AUTOSAR XML (schema 4-0-3)
package /ComponentTypes
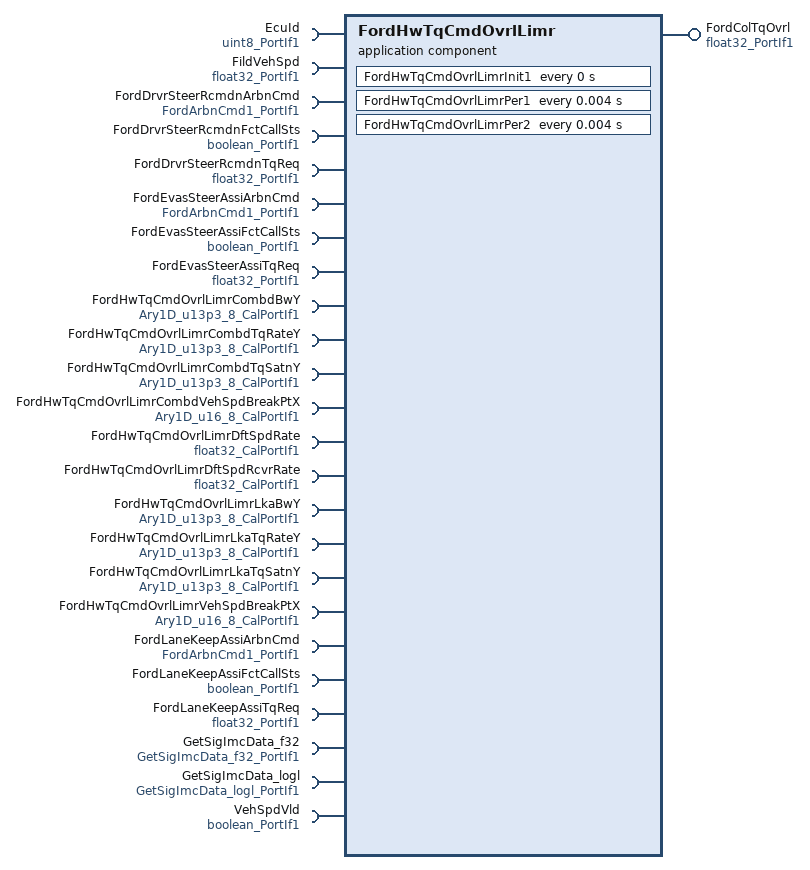
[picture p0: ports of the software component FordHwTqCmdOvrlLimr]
  application sw component type FordHwTqCmdOvrlLimr
    provide port FordColTqOvrl: nonqueued-sender-com-spec{data-element=Val, init-value=0}, provided-interface=float32_PortIf1
    24 x require port:
      EcuId: nonqueued-receiver-com-spec{data-element=Val, filter=data-filter-type=ALWAYS, init-value=0}, required-interface=uint8_PortIf1
      FildVehSpd: nonqueued-receiver-com-spec{data-element=Val, filter=data-filter-type=ALWAYS, init-value=100}, required-interface=float32_PortIf1
      FordDrvrSteerRcmdnArbnCmd: nonqueued-receiver-com-spec{data-element=Val, filter=data-filter-type=ALWAYS, init-value=0}, required-interface=FordArbnCmd1_PortIf1
      FordDrvrSteerRcmdnFctCallSts: nonqueued-receiver-com-spec{data-element=Logl, filter=data-filter-type=ALWAYS, init-value=0}, required-interface=boolean_PortIf1
      FordDrvrSteerRcmdnTqReq: nonqueued-receiver-com-spec{data-element=Val, filter=data-filter-type=ALWAYS, init-value=0}, required-interface=float32_PortIf1
      FordEvasSteerAssiArbnCmd: nonqueued-receiver-com-spec{data-element=Val, filter=data-filter-type=ALWAYS, init-value=0}, required-interface=FordArbnCmd1_PortIf1
      FordEvasSteerAssiFctCallSts: nonqueued-receiver-com-spec{data-element=Logl, filter=data-filter-type=ALWAYS, init-value=0}, required-interface=boolean_PortIf1
      FordEvasSteerAssiTqReq: nonqueued-receiver-com-spec{data-element=Val, filter=data-filter-type=ALWAYS, init-value=0}, required-interface=float32_PortIf1
      FordHwTqCmdOvrlLimrCombdBwY: parameter-require-com-spec{init-value=8 x 0, parameter=Ary1D}, required-interface=Ary1D_u13p3_8_CalPortIf1
      FordHwTqCmdOvrlLimrCombdTqRateY: parameter-require-com-spec{init-value=8 x 64, parameter=Ary1D}, required-interface=Ary1D_u13p3_8_CalPortIf1
      FordHwTqCmdOvrlLimrCombdTqSatnY: parameter-require-com-spec{init-value=8 x 0, parameter=Ary1D}, required-interface=Ary1D_u13p3_8_CalPortIf1
      FordHwTqCmdOvrlLimrCombdVehSpdBreakPtX: parameter-require-com-spec{init-value=[0, 15, 60, 100, 150, 180, 200, 250], parameter=Ary1D}, required-interface=Ary1D_u16_8_CalPortIf1
      FordHwTqCmdOvrlLimrDftSpdRate: parameter-require-com-spec{init-value=40, parameter=Val}, required-interface=float32_CalPortIf1
      FordHwTqCmdOvrlLimrDftSpdRcvrRate: parameter-require-com-spec{init-value=40, parameter=Val}, required-interface=float32_CalPortIf1
      FordHwTqCmdOvrlLimrLkaBwY: parameter-require-com-spec{init-value=8 x 0, parameter=Ary1D}, required-interface=Ary1D_u13p3_8_CalPortIf1
      FordHwTqCmdOvrlLimrLkaTqRateY: parameter-require-com-spec{init-value=8 x 40, parameter=Ary1D}, required-interface=Ary1D_u13p3_8_CalPortIf1
      FordHwTqCmdOvrlLimrLkaTqSatnY: parameter-require-com-spec{init-value=8 x 0, parameter=Ary1D}, required-interface=Ary1D_u13p3_8_CalPortIf1
      FordHwTqCmdOvrlLimrVehSpdBreakPtX: parameter-require-com-spec{init-value=[0, 15, 60, 100, 150, 180, 200, 250], parameter=Ary1D}, required-interface=Ary1D_u16_8_CalPortIf1
      FordLaneKeepAssiArbnCmd: nonqueued-receiver-com-spec{data-element=Val, filter=data-filter-type=ALWAYS, init-value=0}, required-interface=FordArbnCmd1_PortIf1
      FordLaneKeepAssiFctCallSts: nonqueued-receiver-com-spec{data-element=Logl, filter=data-filter-type=ALWAYS, init-value=0}, required-interface=boolean_PortIf1
      FordLaneKeepAssiTqReq: nonqueued-receiver-com-spec{data-element=Val, filter=data-filter-type=ALWAYS, init-value=0}, required-interface=float32_PortIf1
      GetSigImcData_f32: required-interface=GetSigImcData_f32_PortIf1
      GetSigImcData_logl: required-interface=GetSigImcData_logl_PortIf1
      VehSpdVld: nonqueued-receiver-com-spec{data-element=Logl, filter=data-filter-type=ALWAYS, init-value=1}, required-interface=boolean_PortIf1
    behavior FordHwTqCmdOvrlLimr_InternalBehavior
      ar-typed-per-instance-memorys:
        6 x data, all with sw-calibration-access=READ-ONLY:
          LimrDftVehSpd: type=boolean
          LimrVehSpdPrev: type=float32
          LkaTqReqPrev: type=float32
          PrevDftVehSpd: type=float32
          PrevVehSpd: type=float32
          TqReqPrev: type=float32
      timing event FordHwTqCmdOvrlLimr_InitEvent: start-on-event=FordHwTqCmdOvrlLimrInit1, period=0
      timing event TMT_FordHwTqCmdOvrlLimrPer1: start-on-event=FordHwTqCmdOvrlLimrPer1, period=0.004
      timing event TMT_FordHwTqCmdOvrlLimrPer2: start-on-event=FordHwTqCmdOvrlLimrPer2, period=0.004
      explicit-inter-runnable-variables:
        8 x data:
          DrvrSteerRcmdnFctCallSts: type=boolean, init-value=0
          DrvrSteerRcmdnTqReq: type=float32, init-value=0
          EvasSteerAssiFctCallSts: type=boolean, init-value=0
          EvasSteerAssiTqReq: type=float32, init-value=0
          FildVehSpdVal: type=float32, init-value=100
          LaneKeepAssiFctCallSts: type=boolean, init-value=0
          LaneKeepAssiTqReq: type=float32, init-value=0
          VehSpdVldVal: type=boolean, init-value=1
      port-api-options:
        enable-take-address=false, indirect-api=false, port=EcuId
        enable-take-address=false, indirect-api=false, port=FildVehSpd
        enable-take-address=false, indirect-api=false, port=FordColTqOvrl
        enable-take-address=false, indirect-api=false, port=FordDrvrSteerRcmdnArbnCmd
        enable-take-address=false, indirect-api=false, port=FordDrvrSteerRcmdnFctCallSts
        enable-take-address=false, indirect-api=false, port=FordDrvrSteerRcmdnTqReq
        enable-take-address=false, indirect-api=false, port=FordEvasSteerAssiArbnCmd
        enable-take-address=false, indirect-api=false, port=FordEvasSteerAssiFctCallSts
        enable-take-address=false, indirect-api=false, port=FordEvasSteerAssiTqReq
        enable-take-address=false, indirect-api=false, port=FordHwTqCmdOvrlLimrCombdBwY
        enable-take-address=false, indirect-api=false, port=FordHwTqCmdOvrlLimrCombdTqRateY
        enable-take-address=false, indirect-api=false, port=FordHwTqCmdOvrlLimrCombdTqSatnY
        enable-take-address=false, indirect-api=false, port=FordHwTqCmdOvrlLimrCombdVehSpdBreakPtX
        enable-take-address=false, indirect-api=false, port=FordHwTqCmdOvrlLimrDftSpdRate
        enable-take-address=false, indirect-api=false, port=FordHwTqCmdOvrlLimrDftSpdRcvrRate
        enable-take-address=false, indirect-api=false, port=FordHwTqCmdOvrlLimrLkaBwY
        enable-take-address=false, indirect-api=false, port=FordHwTqCmdOvrlLimrLkaTqRateY
        enable-take-address=false, indirect-api=false, port=FordHwTqCmdOvrlLimrLkaTqSatnY
        enable-take-address=false, indirect-api=false, port=FordHwTqCmdOvrlLimrVehSpdBreakPtX
        enable-take-address=false, indirect-api=false, port=FordLaneKeepAssiArbnCmd
        enable-take-address=false, indirect-api=false, port=FordLaneKeepAssiFctCallSts
        enable-take-address=false, indirect-api=false, port=FordLaneKeepAssiTqReq
        enable-take-address=false, indirect-api=false, port=GetSigImcData_f32
        enable-take-address=false, indirect-api=false, port=GetSigImcData_logl
        enable-take-address=false, indirect-api=false, port=VehSpdVld
      runnable FordHwTqCmdOvrlLimrInit1
      runnable FordHwTqCmdOvrlLimrPer1
        data-receive-point-by-arguments:
          access REC_FordDrvrSteerRcmdnArbnCmd_Val: accessed-variable=FordDrvrSteerRcmdnArbnCmd.Val
          access REC_FordEvasSteerAssiArbnCmd_Val: accessed-variable=FordEvasSteerAssiArbnCmd.Val
          access REC_FordLaneKeepAssiArbnCmd_Val: accessed-variable=FordLaneKeepAssiArbnCmd.Val
        data-send-points:
          access SEND_FordColTqOvrl_Val: accessed-variable=FordColTqOvrl.Val
        read-local-variables:
          8 x access:
            READ_DrvrSteerRcmdnFctCallSts: accessed-variable=DrvrSteerRcmdnFctCallSts
            READ_DrvrSteerRcmdnTqReq: accessed-variable=DrvrSteerRcmdnTqReq
            READ_EvasSteerAssiFctCallSts: accessed-variable=EvasSteerAssiFctCallSts
            READ_EvasSteerAssiTqReq: accessed-variable=EvasSteerAssiTqReq
            READ_FildVehSpdVal: accessed-variable=FildVehSpdVal
            READ_LaneKeepAssiFctCallSts: accessed-variable=LaneKeepAssiFctCallSts
            READ_LaneKeepAssiTqReq: accessed-variable=LaneKeepAssiTqReq
            READ_VehSpdVldVal: accessed-variable=VehSpdVldVal
      runnable FordHwTqCmdOvrlLimrPer2
        data-receive-point-by-arguments:
          9 x access:
            REC_EcuId_Val: accessed-variable=EcuId.Val
            REC_FildVehSpd_Val: accessed-variable=FildVehSpd.Val
            REC_FordDrvrSteerRcmdnFctCallSts_Logl: accessed-variable=FordDrvrSteerRcmdnFctCallSts.Logl
            REC_FordDrvrSteerRcmdnTqReq_Val: accessed-variable=FordDrvrSteerRcmdnTqReq.Val
            REC_FordEvasSteerAssiFctCallSts_Logl: accessed-variable=FordEvasSteerAssiFctCallSts.Logl
            REC_FordEvasSteerAssiTqReq_Val: accessed-variable=FordEvasSteerAssiTqReq.Val
            REC_FordLaneKeepAssiFctCallSts_Logl: accessed-variable=FordLaneKeepAssiFctCallSts.Logl
            REC_FordLaneKeepAssiTqReq_Val: accessed-variable=FordLaneKeepAssiTqReq.Val
            REC_VehSpdVld_Logl: accessed-variable=VehSpdVld.Logl
        sync call SC_GetSigImcData_f32_Oper: operation=GetSigImcData_f32.Oper, timeout=0
        sync call SC_GetSigImcData_logl_Oper: operation=GetSigImcData_logl.Oper, timeout=0
        written-local-variables:
          8 x access:
            WRITE_DrvrSteerRcmdnFctCallSts: accessed-variable=DrvrSteerRcmdnFctCallSts
            WRITE_DrvrSteerRcmdnTqReq: accessed-variable=DrvrSteerRcmdnTqReq
            WRITE_EvasSteerAssiFctCallSts: accessed-variable=EvasSteerAssiFctCallSts
            WRITE_EvasSteerAssiTqReq: accessed-variable=EvasSteerAssiTqReq
            WRITE_FildVehSpdVal: accessed-variable=FildVehSpdVal
            WRITE_LaneKeepAssiFctCallSts: accessed-variable=LaneKeepAssiFctCallSts
            WRITE_LaneKeepAssiTqReq: accessed-variable=LaneKeepAssiTqReq
            WRITE_VehSpdVldVal: accessed-variable=VehSpdVldVal
  swc implementation FordHwTqCmdOvrlLimr_Implementation: behavior=FordHwTqCmdOvrlLimr_InternalBehavior
    code-descriptors:
      code Default: artifact-descriptors=autosar-engineering-object={short-label=Default, category=SWSRC}
